# BL702 register map
Vendor: Bouffalo Lab; Series: WiFi BT; File version: 1.0
Registers are 32-bit, read-write, reset 0x0 unless marked. A register's access mark holds for its fields unless they carry their own. Offsets are from the block's base; [hi:lo] are bit positions; {n}, {i} and the like mark numbered series.

## IR — IR Remote control
Base 0x4000A600
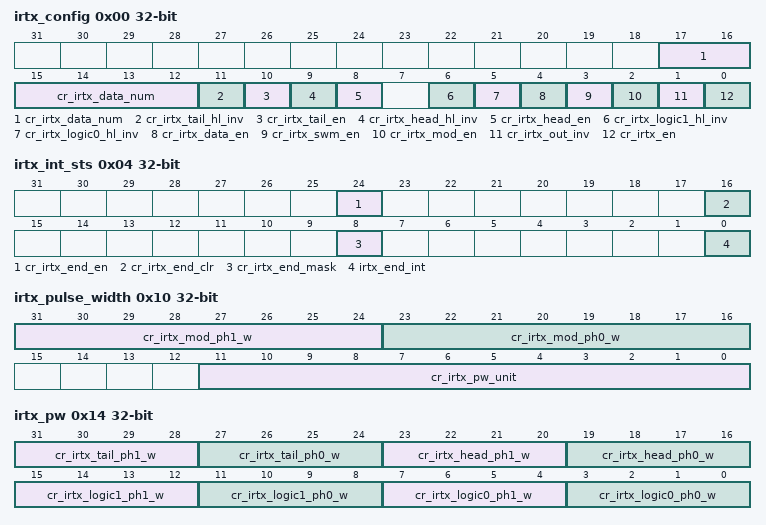
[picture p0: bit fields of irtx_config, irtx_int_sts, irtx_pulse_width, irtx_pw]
0x00 irtx_config
  [17:12] cr_irtx_data_num, [11] cr_irtx_tail_hl_inv, [10] cr_irtx_tail_en, [9] cr_irtx_head_hl_inv, [8] cr_irtx_head_en, [6] cr_irtx_logic1_hl_inv, [5] cr_irtx_logic0_hl_inv, [4] cr_irtx_data_en, [3] cr_irtx_swm_en, [2] cr_irtx_mod_en, [1] cr_irtx_out_inv, [0] cr_irtx_en
0x04 irtx_int_sts
  [24] cr_irtx_end_en, [16] cr_irtx_end_clr, [8] cr_irtx_end_mask, [0] irtx_end_int
0x08 irtx_data_word0
  [31:0] cr_irtx_data_word0
0x0C irtx_data_word1
  [31:0] cr_irtx_data_word1
0x10 irtx_pulse_width
  [31:24] cr_irtx_mod_ph1_w, [23:16] cr_irtx_mod_ph0_w, [11:0] cr_irtx_pw_unit
0x14 irtx_pw
  [31:28] cr_irtx_tail_ph1_w, [27:24] cr_irtx_tail_ph0_w, [23:20] cr_irtx_head_ph1_w, [19:16] cr_irtx_head_ph0_w, [15:12] cr_irtx_logic1_ph1_w, [11:8] cr_irtx_logic1_ph0_w, [7:4] cr_irtx_logic0_ph1_w, [3:0] cr_irtx_logic0_ph0_w
{0x40+4i} irtx_swm_pw_{i} (i=0..7)
  [31:0] cr_irtx_swm_pw_{i}
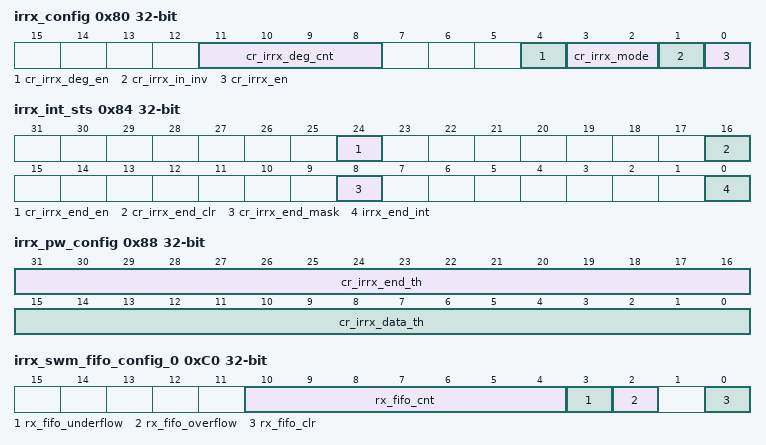
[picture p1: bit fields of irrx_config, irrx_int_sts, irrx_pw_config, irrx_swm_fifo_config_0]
0x80 irrx_config
  [11:8] cr_irrx_deg_cnt, [4] cr_irrx_deg_en, [3:2] cr_irrx_mode, [1] cr_irrx_in_inv, [0] cr_irrx_en
0x84 irrx_int_sts
  [24] cr_irrx_end_en, [16] cr_irrx_end_clr, [8] cr_irrx_end_mask, [0] irrx_end_int
0x88 irrx_pw_config
  [31:16] cr_irrx_end_th, [15:0] cr_irrx_data_th
0x90 irrx_data_count
  [6:0] sts_irrx_data_cnt
0x94 irrx_data_word0
  [31:0] sts_irrx_data_word0
0x98 irrx_data_word1
  [31:0] sts_irrx_data_word1
0xC0 irrx_swm_fifo_config_0
  [10:4] rx_fifo_cnt, [3] rx_fifo_underflow, [2] rx_fifo_overflow, [0] rx_fifo_clr
0xC4 irrx_swm_fifo_rdata
  [15:0] rx_fifo_rdata

## CKS — Checksum
Base 0x4000A700
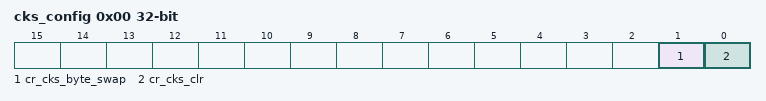
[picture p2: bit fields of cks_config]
0x00 cks_config
  [1] cr_cks_byte_swap, [0] cr_cks_clr
0x04 data_in
  [7:0] data_in
0x08 cks_out
  [15:0] cks_out

## QDEC0 — Quadrature decoder control
Base 0x4000A800
Same registers: QDEC1 0x4000A840, QDEC2 0x4000A880
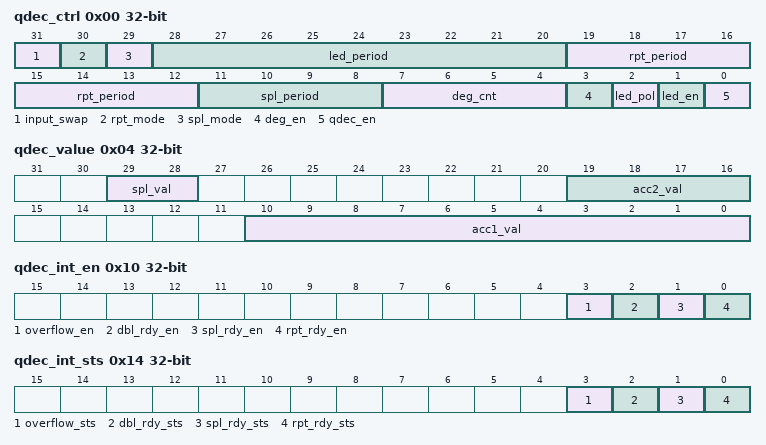
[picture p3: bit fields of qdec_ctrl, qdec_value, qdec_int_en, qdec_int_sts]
0x00 qdec_ctrl
  [31] input_swap, [30] rpt_mode, [29] spl_mode, [28:20] led_period, [19:12] rpt_period, [11:8] spl_period, [7:4] deg_cnt, [3] deg_en, [2] led_pol, [1] led_en, [0] qdec_en
0x04 qdec_value
  [29:28] spl_val, [19:16] acc2_val, [10:0] acc1_val
0x10 qdec_int_en
  [3] overflow_en, [2] dbl_rdy_en, [1] spl_rdy_en, [0] rpt_rdy_en
0x14 qdec_int_sts
  [3] overflow_sts, [2] dbl_rdy_sts, [1] spl_rdy_sts, [0] rpt_rdy_sts
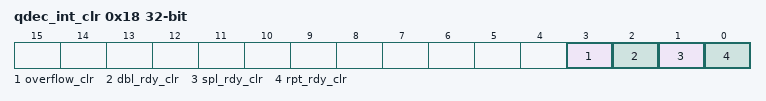
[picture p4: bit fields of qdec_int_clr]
0x18 qdec_int_clr
  [3] overflow_clr, [2] dbl_rdy_clr, [1] spl_rdy_clr, [0] rpt_rdy_clr

## KYS — Key-scan control
Base 0x4000AB00
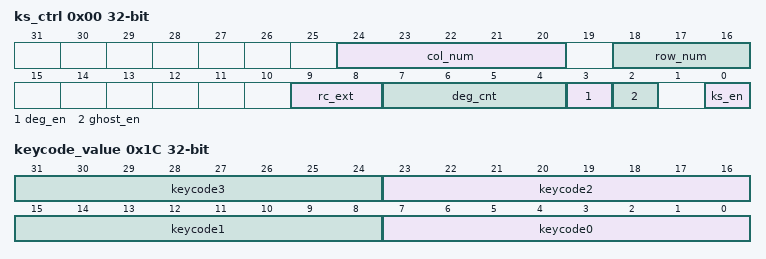
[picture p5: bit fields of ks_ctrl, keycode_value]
0x00 ks_ctrl
  [24:20] col_num, [18:16] row_num, [9:8] rc_ext, [7:4] deg_cnt, [3] deg_en, [2] ghost_en, [0] ks_en
0x10 ks_int_en
  [0] ks_int_en
0x14 ks_int_sts
  [3:0] keycode_valid
0x18 keycode_clr
  [3:0] keycode_clr
0x1C keycode_value
  [8n+7:8n] keycode{n} (n=0..3)

## I2S — I2S control
Base 0x4000AA00
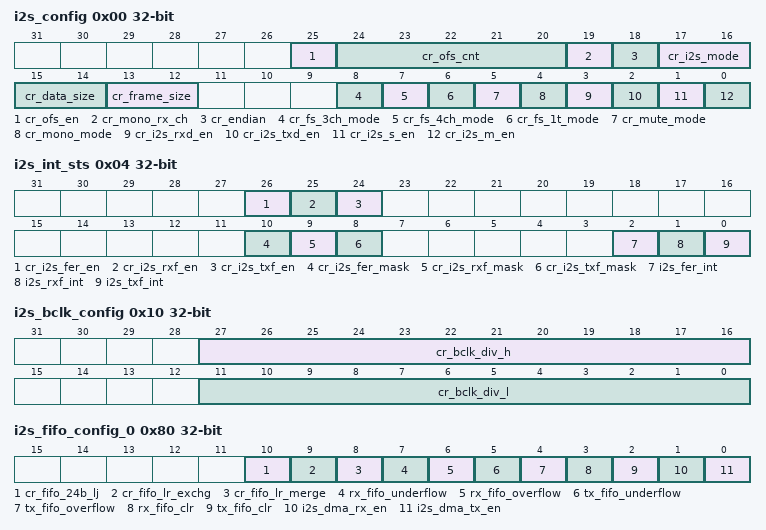
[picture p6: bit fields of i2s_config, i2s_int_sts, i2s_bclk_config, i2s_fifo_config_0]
0x00 i2s_config
  [25] cr_ofs_en, [24:20] cr_ofs_cnt, [19] cr_mono_rx_ch, [18] cr_endian, [17:16] cr_i2s_mode, [15:14] cr_data_size, [13:12] cr_frame_size, [8] cr_fs_3ch_mode, [7] cr_fs_4ch_mode, [6] cr_fs_1t_mode, [5] cr_mute_mode, [4] cr_mono_mode, [3] cr_i2s_rxd_en, [2] cr_i2s_txd_en, [1] cr_i2s_s_en, [0] cr_i2s_m_en
0x04 i2s_int_sts
  [26] cr_i2s_fer_en, [25] cr_i2s_rxf_en, [24] cr_i2s_txf_en, [10] cr_i2s_fer_mask, [9] cr_i2s_rxf_mask, [8] cr_i2s_txf_mask, [2] i2s_fer_int, [1] i2s_rxf_int, [0] i2s_txf_int
0x10 i2s_bclk_config
  [27:16] cr_bclk_div_h, [11:0] cr_bclk_div_l
0x80 i2s_fifo_config_0
  [10] cr_fifo_24b_lj, [9] cr_fifo_lr_exchg, [8] cr_fifo_lr_merge, [7] rx_fifo_underflow, [6] rx_fifo_overflow, [5] tx_fifo_underflow, [4] tx_fifo_overflow, [3] rx_fifo_clr, [2] tx_fifo_clr, [1] i2s_dma_rx_en, [0] i2s_dma_tx_en
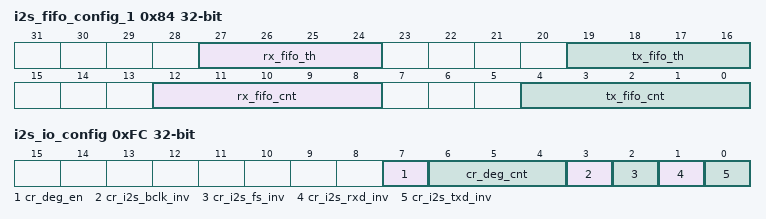
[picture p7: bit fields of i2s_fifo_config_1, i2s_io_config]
0x84 i2s_fifo_config_1
  [27:24] rx_fifo_th, [19:16] tx_fifo_th, [12:8] rx_fifo_cnt, [4:0] tx_fifo_cnt
0x88 i2s_fifo_wdata
0x8C i2s_fifo_rdata
0xFC i2s_io_config
  [7] cr_deg_en, [6:4] cr_deg_cnt, [3] cr_i2s_bclk_inv, [2] cr_i2s_fs_inv, [1] cr_i2s_rxd_inv, [0] cr_i2s_txd_inv
